# pse84 register map
Vendor: Cypress Semiconductor; Series: PSE84; File version: 1.0
CPU: CM33 r0p1, little endian, MPU, FPU, VTOR, 3 interrupt priority bits
Registers are 32-bit, read-write, reset 0x0 unless marked. A register's access mark holds for its fields unless they carry their own. Offsets are from the block's base; [hi:lo] are bit positions; lines under a group give offsets from that group; {n}, {i} and the like mark numbered series; 'fields as' and 'values as' point back to an identical list; <NAME> marks a mode.

## DAC0 — DAC
Base 0x42E60000
Same registers: DAC1 0x42E70000
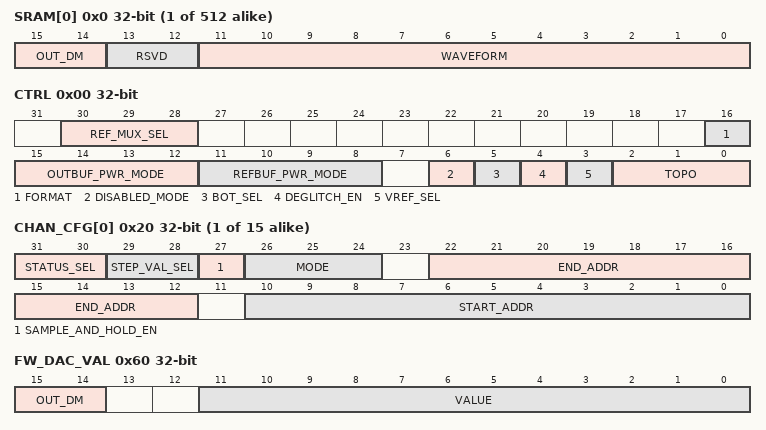
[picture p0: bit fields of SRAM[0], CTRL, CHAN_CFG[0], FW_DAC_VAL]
{0x0+4i} SRAM[{i}] (i=0..511) — SRAM Waveform Table (only accessible if ACTRLR.STATUS.MODE=0)
  [15:14] OUT_DM — DAC Output Drive Mode
    0=OUT_EN (DAC output enabled (outputs WAVEFORM)); 1=OUT_HIZ (DAC output disabled (output is Tri-state)); 2=OUT_REF (DAC output disabled (output Vssa or Vref when disabled (see CTRL.BOT_SEL))); 3=RSVD (N/A)
  [13:12] RSVD
  [11:0] WAVEFORM — DAC waveform
0x800 STA group — DAC static configuration registers
  0x00 CTRL — DAC control register (only accessible if ACTRLR.STATUS.MODE=0)
    [30:28] REF_MUX_SEL — DAC reference mux output select
      0=VBGR (DAC reference mux is driven by the AREF bandgap output (source selected by AREF.CTRL.VREF_SEL)); 1=CTBL0_OA0 (CTBL0 Opamp0 Output); 2=CTBL0_OA1 (CTBL0 Opamp1 Output); 3=CTBL1_OA0 (CTBL1 Opamp0 Output); 4=CTBL1_OA1 (CTBL1 Opamp1 Output); 5=VDDA (Do Not Use); 6=PRB_VREF0 (PRB VREF0 output); 7=PRB_VREF1 (PRB VREF1 output)
    [16] FORMAT — DAC output format select
      0=UNSIGNED12 (Unsigned 12-bit number, i.e. no value decoding); 1=VIRT_SIGNED12 (Virtual signed 12-bits' VDAC. Value decoding: add 0x800 to the 12-bit Value (=invert MSB), to convert the lowest signed number 0x800 to the lowest unsigned number 0x000. This is the same as the SAR handles 12-bit 'virtual' signed numbers.)
    [15:12] OUTBUF_PWR_MODE — Output buffer power level
      0=OFF; 1=ULTRA_LOW (If TOPO=BUFFERED_INTERNAL: quiscent current of 15uA, input common mode of 0.2V to VDDA-1V, gain bandwidth of 30kHz. If TOPO=BUFFERED_EXTERNAL: quiscent current of 15uA, input common mode of 0.2V to VDDA-1V, gain bandwidth of 100kHz, 10uA output drive capability.); 2=ULTRA_LOW_RAIL (If TOPO=BUFFERED_INTERNAL: quiscent current of 35uA, input common mode of 0.2V to VDDA-0.2V, gain bandwidth of 30kHz. If TOPO=BUFFERED_EXTERNAL: quiscent current of 35uA, input common mode of 0.2V to VDDA-0.2V, gain bandwidth of 100kHz, 10uA output drive capability.); 3=LOW (Do Not Use); 4=LOW_RAIL (If TOPO=BUFFERED_INTERNAL: quiscent current of 150uA, input common mode of 0.2V to VDDA-0.2V, gain bandwidth of 350kHz. If TOPO=BUFFERED_EXTERNAL: quiscent current of 150uA, input common mode of 0.2V to VDDA-0.2V, gain bandwidth of 1.2MHz, 100uA output drive capability.); 5=MEDIUM (Do Not Use); 6=MEDIUM_RAIL (If TOPO=BUFFERED_INTERNAL: quiscent current of 200uA, input common mode of 0.2V to VDDA-0.2V, gain bandwidth of 700kHz. If TOPO=BUFFERED_EXTERNAL: quiscent current of 200uA, input common mode of 0.2V to VDDA-0.2V, gain bandwidth of 2.4MHz, 1mA output drive capability.); 7=HIGH (Do Not Use); 8=HIGH_RAIL (If TOPO=BUFFERED_INTERNAL: quiscent current of 600uA, input common mode of 0.2V to VDDA-0.2V, gain bandwidth of 1.75MHz. If TOPO=BUFFERED_EXTERNAL: quiscent current of 600uA, input common mode of 0.2V to VDDA-0.2V, gain bandwidth of 6MHz,1mA output drive capability.); 9=ULTRA_HIGH (Do Not Use); 10=ULTRA_HIGH_RAIL (If TOPO=BUFFERED_INTERNAL: quiscent current of 800uA, input common mode of 0.2V to VDDA-0.2V, gain bandwidth of 2.8MHz. If TOPO=BUFFERED_EXTERNAL: quiscent current of 800uA, input common mode of 0.2V to VDDA-0.2V, gain bandwidth of 7.5MHz, 10mA output drive capability.); {v}=RSVD_{v-11} (N/A) (v=11..15)
    [11:8] REFBUF_PWR_MODE — Reference buffer power level
      0=OFF; 1=ULTRA_LOW (reference buffer quiscent current of 15uA, input common mode of 0.2V to VDDA-1V, gain bandwidth of 30kHz.); 2=ULTRA_LOW_RAIL (reference buffer quiscent current of 35uA, input common mode of 0.2V to VDDA-0.2V, gain bandwidth of 30kHz.); 3=LOW (Do Not Use); 4=LOW_RAIL (reference buffer quiscent current of 150uA, input common mode of 0.2V to VDDA-0.2V, gain bandwidth of 350kHz.); 5=MEDIUM (Do Not Use); 6=MEDIUM_RAIL (reference buffer quiscent current of 200uA, input common mode of 0.2V to VDDA-0.2V, gain bandwidth of 700kHz.); 7=HIGH (Do Not Use); 8=HIGH_RAIL (reference buffer quiscent current of 600uA, input common mode of 0.2V to VDDA-0.2V, gain bandwidth of 1.75MHz.); 9=ULTRA_HIGH (Do Not Use); 10=ULTRA_HIGH_RAIL (reference buffer quiscent current of 800uA, input common mode of 0.2V to VDDA-0.2V, gain bandwidth of 2.8MHz.); {v}=RSVD_{v-11} (N/A) (v=11..15)
    [6] DISABLED_MODE — Select the output value when the output is disabled 0: Tri-state CTDAC output when disabled 1: output Vssa or Vref when disabled (see BOT_SEL description)
    [5] BOT_SEL — Bottom connection select to R2R network. 0: Connect to VSSA: DAC enabled: when DM_OUT=OUT_EN, the DAC range is [0, 4095] * Vref / 4096, when DM_OUT=OUT_REF, the DAC outputs VSSA. DAC disabled and DISABLED_MODE=1, the DAC outputs VSSA. 1: Connect to VREF: DAC enabled: when DM_OUT=OUT_EN, the DAC range is [1, 4096] * Vref / 4096, when DM_OUT=OUT_REF, the DAC outputs VREF. DAC disabled and DISABLED_MODE=1, the DAC outputs VREF.
    [4] DEGLITCH_EN — Deglitch enable This field is used to prevent glitches after the DAC output changes by opening the output switch for (open time set by DEGLITCH_TIME). If TOPO is set to 0-2, CHO switch is opened during deglitch time, if TOPO is set to 3,4, COS switch is opened during deglitch time.
      0=DISABLED (N/A); 1=ENABLED (N/A)
    [3] VREF_SEL — DAC reference select
      0=VREF_MUX_OUT (DAC reference is driven by the reference mux (see REF_MUX_SEL). This selection requires that REFBUF_PWR_MODE be set to a value other than OFF.); 1=VDDA (DAC reference is driven directly from VDDA. Since this path does not use the DAC reference buffer, REFBUF_PWR_MODE should be set to OFF.)
    [2:0] TOPO — DAC Topology
      0=DIRECT (DAC drives output directly); 1=DIRECT_WITH_TRACK_CAP (DAC drives output directly with Track Cap on output); 2=DIRECT_WITH_TRACK_HOLD_CAP (DAC drives output directly with Track and Hold Cap on output); 3=BUFFERED_INTERNAL (DAC output is buffered (internal connections only)); 4=BUFFERED_EXTERNAL (DAC output is buffered for internal or external connections); 5=RSVD_0 (N/A); 6=RSVD_1 (N/A); 7=RSVD_2 (N/A)
  0x04 SAMPLE_TIME — Sample control register (only accessible if ACTRLR.STATUS.MODE=0)
    [7:0] SAMPLE_TIME — Sample Time selection for Sample and Hold Modes This field is only used if enabled DAC channel is configured for sample and hold operation (i.e. CHAN_CFG.SAMPLE_AND_HOLD_EN=1) The sample time is measured in terms of CLK_HF (nominally 80MHz) cycles (if ACTRLR.STATUS.MODE=HS) or CLK_LPOSC (nominally 4.096MHz) cycles (if ACTRLR.STATUS.MODE=LP). Sample time = SAMPLE_TIME+1, range 1..256
  {0x8+4j} STEP_VAL[{j}] (j=0..2) — step val register (only accessible if ACTRLR.STATUS.MODE=0)
    [7:0] VAL — DAC step value. Actual step value is VAL+1. Step Type (address or data) is set by CHAN_CFG.MODE. The maximim allowable step value is set by the operational mode as follows: If CHAN_CFG.MODE= LUT_OS_ONE_QUAD, LUT_CONT_ONE_QUAD or ADDR: Max step size = (CHAN_CFG.END_ADDR - CHAN_CFG.START_ADDR + 1) If CHAN_CFG.MODE= LUT_OS_TWO_QUAD, LUT_OS_FOUR_QUAD, LUT_CONT_TWO_QUAD, LUT_CONT_FOUR_QUAD: Max step size = (CHAN_CFG.END_ADDR - CHAN_CFG.START_ADDR) If CHAN_CFG.MODE = DATA, there is no max step size. If the programmed step size exceeds the Max step size, the hardware not not advance the address pointer, and an EPOCH will be produced every DAC_CLOCK_EN.
  0x18 DEGLITCH_TIME reset 0x1 — deglitch time register (only accessible if ACTRLR.STATUS.MODE=0)
    [7:0] DEGLITCH_TIME — Geglitch Time selection for DAC value updates This field is only used if CTRL.DEGLITCH_EN=1. The deglitch time is measured in terms of CLK_HF (nominally 80MHz) cycles (if ACTRLR.STATUS.MODE=HS) or CLK_LPOSC (nominally 4.096MHz) cycles (if ACTRLR.STATUS.MODE=LP). Deglitch time = GEGLITCH_TIME+1, range 1..256
  {0x20+4j} CHAN_CFG[{j}] (j=0..14) — Channel configuration register (only accessible if ACTRLR.STATUS.MODE=0)
    [31:30] STATUS_SEL — Status selections.
      0=DISABLED (N/A); 1=STATUS_0 (N/A); 2=STATUS_1 (N/A); 3=STATUS_2 (N/A)
    [29:28] STEP_VAL_SEL — DAC Step Value Selection
      0=DISABLED (STEP_VAL is 1.); 1=STEP_0 (STEP_VAL is set by STEP_VAL0.VAL.); 2=STEP_1 (STEP_VAL is set by STEP_VAL1.VAL.); 3=STEP_2 (STEP_VAL is set by STEP_VAL2.VAL.)
    [27] SAMPLE_AND_HOLD_EN — DAC Sample and Hold Enable SAMPLE_AND_HOLD_EN can only be selected if CTRL.TOPO=BUFFERED_INTERNAL or BUFFERED_EXTERNAL. The DAC is updated every positive edge of the DAC clock with the following sequence: 1. The DAC is configured for SAMPLE: DAC array is enabled and outputs the updated value (based on MODE) onto a capacitor for SAMPLE_TIME duration. 2. The DAC is configured for HOLD: DAC array is disabled and last output value is held on capacitor until next positive edge of the DAC clock (HOLD duration is DAC clock period - SAMPLE_TIME) *NOTE: For MODE=ADDRESS or DATA, the AC must wait for (ACT=WAIT_FOR) the DAC strobe (COND=DAC_STROBE) before re-triggering the DAC_INC/DAC_DEC fields.
    [26:24] MODE — DAC operating mode
      0=LUT_OS_ONE_QUAD (DAC configured for One Shot One Quadrant LUT mode. LUT address increments every positive edge of the DAC clock until END_ADDR is reached or exceeded. Update Step size set by STEP_VAL_SEL. The One Shot is completed by the END_ADDR is reached. The DAC outputs an EPOCH trigger after reaching (or exceeding) the END_ADDR and outputing the corresponding value.); 1=LUT_OS_TWO_QUAD (DAC configured for One Shot Two Quadrant LUT mode. LUT address increments every positive edge of the DAC clock until END_ADDR is reached*, then the LUT address decrements back to the START_ADDR. DAC outputs an EPOCH trigger after returning to (or exceeding) the START_ADDR and outputing the START_ADDR value. *NOTE: If the END_ADDR is not reached but instead exceeded (can occur for STEP_VAL_SEL=1,2) then the LUT address is decremented from END_ADDR by the exceeded amount).); 2=LUT_OS_FOUR_QUAD (DAC configured for One Shot Four Quadrant LUT mode. LUT address is updated every positive edge of the DAC clock according to the following algorithm: 1. LUT address increments until END_ADDR is reached*. 2. LUT address decrements until START_ADDR is reached*. 3. Invert polarity and repeat 1 and 2. DAC outputs an EPOCH trigger after returning to (or exceeding) the START_ADDR with an Inverted polarity and outputting the corresponding value. (This mode assumes that the DAC waveform table (stored in SRAM) constitutes 1/4 of the desired generated waveform) *NOTE: If the START/END_ADDR is not reached but instead exceeded (can occur for STEP_VAL_SEL=1,2) then the LUT address is adjusted (i.e. decremented from END_ADDR or incremented from the STAR_ADDR by the amount exceeded).); 3=LUT_CONT_ONE_QUAD (DAC configured for Continuous One Quadrant LUT mode. LUT address increments every positive edge of the DAC clock until END_ADDR is reached*. The address then wraps back to the START_ADDR and repeats indefinitiely. Update Step size set by STEP_VAL_SEL. The DAC outputs an EPOCH trigger after reaching (or exceeding) the END_ADDR and outputing the corresponding value. *NOTE: If the END_ADDR is not reached but instead exceeded (can occur for STEP_VAL_SEL=1,2) then the LUT address wraps back to the STAR_ADDR and is further incremented by the amount exceeded).); 4=LUT_CONT_TWO_QUAD (DAC configured for Continuous Two Quadrant LUT mode. LUT address increments every positive edge of the DAC clock until END_ADDR is reached*, then the LUT address decrements back to the START_ADDR and repeats indefinitely. DAC outputs an EPOCH trigger after returning to the START_ADDR and outputing the START_ADDR value. *NOTE: If the START/END_ADDR is not reached but instead exceeded (can occur for STEP_VAL_SEL=1,2) then the LUT address is adjusted (i.e. decremented from END_ADDR or incremented from the STAR_ADDR by the amount exceeded).); 5=LUT_CONT_FOUR_QUAD (DAC configured for Continuous Four Quadrant LUT mode. LUT address is updated every positive edge of the DAC clock according to the following algorithm: 1. LUT address increments until END_ADDR is reached*. 2. LUT address decrements until START_ADDR is reached*. 3. Invert polarity and repeat 1 and 2 and repeat indefinitely. DAC outputs an EPOCH trigger after returning to (or exceeding) the START_ADDR with an Inverted polarity and outputting the corresponding value. (This mode assumes that the DAC waveform table (stored in SRAM) constitutes 1/4 of the desired generated waveform) *NOTE: If the START/END_ADDR is not reached but instead exceeded (can occur for STEP_VAL_SEL=1,2) then the LUT address is adjusted (i.e. decremented from END_ADDR or incremented from the STAR_ADDR by the amount exceeded).); 6=ADDR (DAC configured for ADDRESS mode Address is updated every positive edge of the DAC_INC or DAC_DEC from AC (unless SAMPLE_AND_HOLD_EN is set). Step size set by STEP_SIZE_EN and STEP_VAL. If on the START_ADDR and DAC_DEC is triggered, the ADDR wraps forward to the END_ADDR. If on the END_ADDR and DAC_INC is triggered, the address wraps back to the START_ADDR. In this mode, the DAC does not output an EPOCH trigger.); 7=DATA (DAC configured for DATA mode DAC outputs the data stored at the start address. The DAC output value is incremented or decremented based on AC.DAC_INC and AC.DAC_DEC The data is updated every positive edge of the DAC_INC or DAC_DEC (unless SAMPLE_AND_HOLD_EN is set). The increment/decrement amount is set by STEP_VAL_SEL. In this mode, the DAC does not output an EPOCH trigger. The DAC value is clamped if requested to go under the minimum code (0x000 for unsigned or 0x800 for signed) or above the maximum code (0xFFF for unsigned or 0x7FF for signed).)
    [22:12] END_ADDR — End of Waveform Address pointer The end address must be greater than or equal to the start address (START_ADDR)
    [10:0] START_ADDR — Start of Waveform Address pointer When triggered (AC_DAC_TR), the DAC outputs the value at START_ADDR
  0x60 FW_DAC_VAL — Firmare Channel DAC Value (only accessible if ACTRLR.STATUS.MODE=0)
    [15:14] OUT_DM — DAC Output Drive Mode
      0=OUT_EN (DAC output enabled (outputs VALUE)); 1=OUT_HIZ (DAC output disabled (output is Tri-state)); 2=OUT_REF (DAC output disabled (output Vssa or Vref when disabled (see CTRL.BOT_SEL))); 3=RSVD (N/A)
    [11:0] VALUE — DAC Value Writes to this register are ignored unless ACTRLR.TIMER_TABLE_STRUCT.TT_CFG3.DAC[X]_CHANNEL=FW_CHANNEL
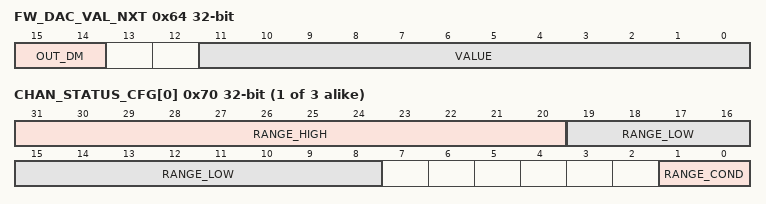
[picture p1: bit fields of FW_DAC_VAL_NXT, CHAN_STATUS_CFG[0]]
  0x64 FW_DAC_VAL_NXT — Firmware Channel DAC Value Next
    [15:14] OUT_DM — DAC Output Drive Mode
      values as STA.FW_DAC_VAL.OUT_DM
    [11:0] VALUE — Next value for FW_DAC_VAL.VALUE Writes to this register are ignored unless ACTRLR.TIMER_TABLE_STRUCT.TT_CFG3.DAC[X]_CHANNEL=FW_CHANNEL
  {0x70+4j} CHAN_STATUS_CFG[{j}] (j=0..2) — Channel status configuration register
    [31:20] RANGE_HIGH — High threshold for range detect
    [19:8] RANGE_LOW — Low threshold for range detect
    [1:0] RANGE_COND — Range condition select.
      0=BELOW (DAC Value < RANGE_LOW); 1=INSIDE (RANGE_LOW <= DAC Value/Address < RANGE_HIGH); 2=ABOVE (DAC Value > RANGE_HIGH); 3=OUTSIDE (Dac Value < RANGE_LOW || DAC Value/Address >= RANGE_HIGH)
  0x80 RANGE_STATUS
    [14:0] CHAN_RANGE_STATUS — Channel Range detect status: hardware sets this bit for each channel if the condition specified by the CHAN_CFG.STATUS_SEL register is met. Write with '1' to clear bit. This register does not apply to the FW Channel (Channel 15).
0xF00 TRIM group — DAC trim registers (only accessible if ACTRLR.STATUS.MODE=0)
  0x00 REFBUF_OFFSET_TRIM — Reference buffer trim control
    [5:0] REFBUF_OFFSET_TRIM
  0x04 REFBUF_SLOPE_OFFSET_TRIM — Reference buffer trim control
    [5:0] REFBUF_SLOPE_OFFSET_TRIM — Refbuf slope offset drift trim
  0x08 REFBUF_COMP_TRIM — Reference buffer trim control
    [3:0] REFBUF_COMP_TRIM — Buffer 0 Compensation Capacitor Trim Bit<3> is not used Bits<2:0> 000 = 0.1pF 001 = 1.1pF 010 = 2.1pF 011 = 3.1pF 100 = 4.1pF 101 = 5.1pF 110 = 6.1pF 111 = 7.1pF
  {0xC+4j} OUTBUF_OFFSET_TRIM[{j}] (j=0..1) — Output buffer trim control
    [5:0] OUTBUF_OFFSET_TRIM
  {0x14+4j} OUTBUF_SLOPE_OFFSET_TRIM[{j}] (j=0..1) — Output buffer trim control
    [5:0] OUTBUF_SLOPE_OFFSET_TRIM — Outbuf slope offset drift trim
  {0x1C+4j} OUTBUF_COMP_TRIM[{j}] (j=0..1) — Output buffer trim control
    [3:0] OUTBUF_COMP_TRIM — see REFBUF_COMP_TRIM.REFBUF_COMP_TRIM
  0x24 RMP_TRIM reset 0x1 — Risk Mitigation bits
    [3:0] RMP_TRIM
